AUTOSAR XML (schema 00048)
package /HuaweiMDC/FunctionalSoftware/TrajectoryPredictionApplication/Execution
  executable TrajectoryPredictionExecutable
    root sw component prototype TrajectoryPredictionRootSwComponent: application-type=TrajectoryPredictionSwComponent
package /HuaweiMDC/FunctionalSoftware/TrajectoryPredictionApplication/SwComponent
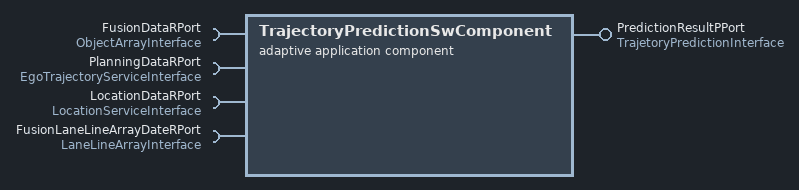
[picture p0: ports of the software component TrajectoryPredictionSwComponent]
  adaptive application sw component type TrajectoryPredictionSwComponent
    require port FusionDataRPort: required-interface=ObjectArrayInterface
    require port PlanningDataRPort: required-interface=EgoTrajectoryServiceInterface
    require port LocationDataRPort: required-interface=LocationServiceInterface
    provide port PredictionResultPPort: provided-interface=TrajetoryPredictionInterface
    require port FusionLaneLineArrayDateRPort: required-interface=LaneLineArrayInterface
